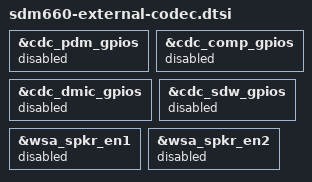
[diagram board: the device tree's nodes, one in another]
&cdc_pdm_gpios {
	status = "disabled";
};

&cdc_comp_gpios {
	status = "disabled";
};

&cdc_dmic_gpios {
	status = "disabled";
};

&cdc_sdw_gpios {
	status = "disabled";
};

&wsa_spkr_en1 {
	status = "disabled";
};

&wsa_spkr_en2 {
	status = "disabled";
};
